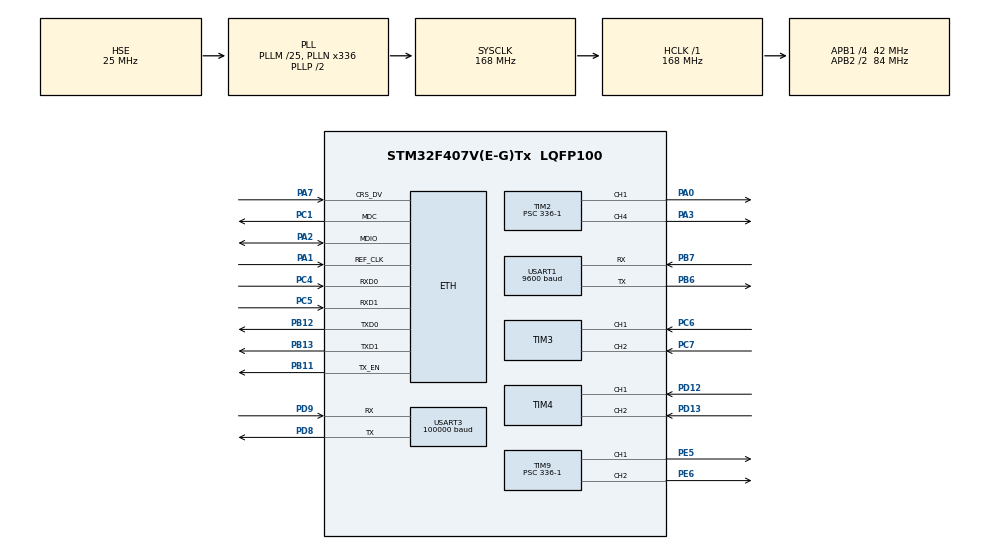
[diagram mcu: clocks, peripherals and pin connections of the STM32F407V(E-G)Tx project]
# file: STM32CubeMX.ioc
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Dma.Request0=USART1_TX
Dma.Request1=USART3_RX
Dma.USART1_TX.0.Direction=DMA_MEMORY_TO_PERIPH
Dma.USART1_TX.0.FIFOMode=DMA_FIFOMODE_DISABLE
Dma.USART1_TX.0.Instance=DMA2_Stream7
Dma.USART1_TX.0.MemDataAlignment=DMA_MDATAALIGN_BYTE
Dma.USART1_TX.0.MemInc=DMA_MINC_ENABLE
Dma.USART1_TX.0.Mode=DMA_NORMAL
Dma.USART1_TX.0.PeriphDataAlignment=DMA_PDATAALIGN_BYTE
Dma.USART1_TX.0.PeriphInc=DMA_PINC_DISABLE
Dma.USART1_TX.0.Priority=DMA_PRIORITY_LOW
Dma.USART3_RX.1.Direction=DMA_PERIPH_TO_MEMORY
Dma.USART3_RX.1.FIFOMode=DMA_FIFOMODE_DISABLE
Dma.USART3_RX.1.Instance=DMA1_Stream1
Dma.USART3_RX.1.MemDataAlignment=DMA_MDATAALIGN_BYTE
Dma.USART3_RX.1.MemInc=DMA_MINC_ENABLE
Dma.USART3_RX.1.Mode=DMA_CIRCULAR
Dma.USART3_RX.1.PeriphDataAlignment=DMA_PDATAALIGN_BYTE
Dma.USART3_RX.1.PeriphInc=DMA_PINC_DISABLE
Dma.USART3_RX.1.Priority=DMA_PRIORITY_LOW
ETH.MediaInterface=HAL_ETH_RMII_MODE
ETH.RxMode=ETH_RXINTERRUPT_MODE
Mcu.Family=STM32F4
Mcu.Name=STM32F407V(E-G)Tx
Mcu.Package=LQFP100
NVIC.DMA1_Stream1_IRQn=true\:4\:0\:true\:false\:true\:false\:true\:true
NVIC.DMA2_Stream7_IRQn=true\:0\:0\:false\:false\:true\:false\:true\:true
NVIC.ETH_IRQn=true\:0\:0\:true\:false\:true\:true\:true\:true
NVIC.ETH_WKUP_IRQn=true\:0\:0\:false\:false\:true\:true\:true\:true
NVIC.PriorityGroup=NVIC_PRIORITYGROUP_4
NVIC.TIM3_IRQn=true\:4\:0\:true\:false\:true\:true\:true\:true
NVIC.TIM4_IRQn=true\:4\:0\:true\:false\:true\:true\:true\:true
NVIC.TIM5_IRQn=true\:4\:0\:true\:false\:true\:true\:true\:true
NVIC.TIM8_TRG_COM_TIM14_IRQn=true\:15\:0\:false\:false\:true\:false\:true\:true
NVIC.TimeBase=TIM8_TRG_COM_TIM14_IRQn
NVIC.TimeBaseIP=TIM14
NVIC.USART1_IRQn=true\:4\:0\:true\:false\:true\:true\:true\:true
NVIC.USART3_IRQn=true\:4\:0\:true\:false\:true\:true\:true\:true
PA0-WKUP.Signal=S_TIM2_CH1_ETR
PA1.Mode=RMII
PA1.Signal=ETH_REF_CLK
PA13.Mode=Serial_Wire
PA13.Signal=SYS_JTMS-SWDIO
PA14.Mode=Serial_Wire
PA14.Signal=SYS_JTCK-SWCLK
PA2.Mode=RMII
PA2.Signal=ETH_MDIO
PA3.Signal=S_TIM2_CH4
PA7.Mode=RMII
PA7.Signal=ETH_CRS_DV
PB11.Mode=RMII
PB11.Signal=ETH_TX_EN
PB12.Mode=RMII
PB12.Signal=ETH_TXD0
PB13.Mode=RMII
PB13.Signal=ETH_TXD1
PB6.Mode=Asynchronous
PB6.Signal=USART1_TX
PB7.Mode=Asynchronous
PB7.Signal=USART1_RX
PC1.Mode=RMII
PC1.Signal=ETH_MDC
PC14-OSC32_IN.Mode=LSE-External-Oscillator
PC14-OSC32_IN.Signal=RCC_OSC32_IN
PC15-OSC32_OUT.Mode=LSE-External-Oscillator
PC15-OSC32_OUT.Signal=RCC_OSC32_OUT
PC4.Mode=RMII
PC4.Signal=ETH_RXD0
PC5.Mode=RMII
PC5.Signal=ETH_RXD1
PC6.Signal=S_TIM3_CH1
PC7.Signal=S_TIM3_CH2
PD12.Signal=S_TIM4_CH1
PD13.Signal=S_TIM4_CH2
PD8.Mode=Asynchronous
PD8.Signal=USART3_TX
PD9.Mode=Asynchronous
PD9.Signal=USART3_RX
PE5.Signal=S_TIM9_CH1
PE6.Signal=S_TIM9_CH2
PH0-OSC_IN.Mode=HSE-External-Oscillator
PH0-OSC_IN.Signal=RCC_OSC_IN
PH1-OSC_OUT.Mode=HSE-External-Oscillator
PH1-OSC_OUT.Signal=RCC_OSC_OUT
ProjectManager.HeapSize=0x200
ProjectManager.StackSize=0x400
ProjectManager.TargetToolchain=MDK-ARM V5.32
RCC.48MHZClocksFreq_Value=84000000
RCC.AHBFreq_Value=168000000
RCC.APB1CLKDivider=RCC_HCLK_DIV4
RCC.APB1Freq_Value=42000000
RCC.APB1TimFreq_Value=84000000
RCC.APB2CLKDivider=RCC_HCLK_DIV2
RCC.APB2Freq_Value=84000000
RCC.APB2TimFreq_Value=168000000
RCC.CortexFreq_Value=168000000
RCC.HCLKFreq_Value=168000000
RCC.HSE_VALUE=25000000
RCC.HSI_VALUE=16000000
RCC.PLLM=25
RCC.PLLN=336
RCC.PLLSourceVirtual=RCC_PLLSOURCE_HSE
RCC.SYSCLKFreq_VALUE=168000000
RCC.SYSCLKSource=RCC_SYSCLKSOURCE_PLLCLK
RCC.VCOOutputFreq_Value=336000000
SH.S_TIM2_CH1_ETR.0=TIM2_CH1,PWM Generation1 CH1
SH.S_TIM2_CH4.0=TIM2_CH4,PWM Generation4 CH4
SH.S_TIM3_CH1.0=TIM3_CH1,Encoder_Interface
SH.S_TIM3_CH2.0=TIM3_CH2,Encoder_Interface
SH.S_TIM4_CH1.0=TIM4_CH1,Encoder_Interface
SH.S_TIM4_CH2.0=TIM4_CH2,Encoder_Interface
SH.S_TIM9_CH1.0=TIM9_CH1,PWM Generation1 CH1
SH.S_TIM9_CH2.0=TIM9_CH2,PWM Generation2 CH2
TIM2.AutoReloadPreload=TIM_AUTORELOAD_PRELOAD_ENABLE
TIM2.Channel-PWM\ Generation1\ CH1=TIM_CHANNEL_1
TIM2.Channel-PWM\ Generation4\ CH4=TIM_CHANNEL_4
TIM2.Period=100-1
TIM2.Prescaler=336-1
TIM3.EncoderMode=TIM_ENCODERMODE_TI12
TIM4.EncoderMode=TIM_ENCODERMODE_TI12
TIM4.IC1Filter=0
TIM4.IC2Filter=15
TIM5.Period=1000-1
TIM5.Prescaler=840-1
TIM9.AutoReloadPreload=TIM_AUTORELOAD_PRELOAD_ENABLE
TIM9.Channel-PWM\ Generation1\ CH1=TIM_CHANNEL_1
TIM9.Channel-PWM\ Generation2\ CH2=TIM_CHANNEL_2
TIM9.Period=100-1
TIM9.Prescaler=336-1
USART1.BaudRate=9600
USART1.Parity=PARITY_EVEN
USART1.VirtualMode=VM_ASYNC
USART1.WordLength=WORDLENGTH_9B
USART3.BaudRate=100000
USART3.Mode=MODE_TX_RX
USART3.Parity=PARITY_EVEN
USART3.StopBits=STOPBITS_2
USART3.VirtualMode=VM_ASYNC
USART3.WordLength=WORDLENGTH_9B
VP_SYS_VS_tim14.Mode=TIM14
VP_TIM2_VS_ClockSourceINT.Mode=Internal
VP_TIM5_VS_ClockSourceINT.Mode=Internal
VP_TIM9_VS_ClockSourceINT.Mode=Internal
board=custom

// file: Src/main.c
/* USER CODE BEGIN Header */
/**
  ******************************************************************************
  * @file           : main.c
  * @brief          : Main program body
  ******************************************************************************
  * @attention
  *
  * Copyright (c) 2025 STMicroelectronics.
  * All rights reserved.
  *
  * This software is licensed under terms that can be found in the LICENSE file
  * in the root directory of this software component.
  * If no LICENSE file comes with this software, it is provided AS-IS.
  *
  ******************************************************************************
  */
/* USER CODE END Header */
#include "main.h"
#include "string.h"

/* USER CODE BEGIN Includes */
#include "RTE_Components.h"
#include CMSIS_device_header
#include "cmsis_os2.h"
#include "rl_net.h"

#include <stdbool.h>
#include "system.h"

/* USER CODE END Includes */

ETH_TxPacketConfig TxConfig;
ETH_DMADescTypeDef  DMARxDscrTab[ETH_RX_DESC_CNT]; /* Ethernet Rx DMA Descriptors */
ETH_DMADescTypeDef  DMATxDscrTab[ETH_TX_DESC_CNT]; /* Ethernet Tx DMA Descriptors */

ETH_HandleTypeDef heth;

TIM_HandleTypeDef htim2;
TIM_HandleTypeDef htim3;
TIM_HandleTypeDef htim4;
TIM_HandleTypeDef htim5;
TIM_HandleTypeDef htim9;

UART_HandleTypeDef huart1;
UART_HandleTypeDef huart3;
DMA_HandleTypeDef hdma_usart1_tx;
DMA_HandleTypeDef hdma_usart3_rx;

void SystemClock_Config(void);
static void MX_GPIO_Init(void);
static void MX_DMA_Init(void);
static void MX_TIM2_Init(void);
static void MX_TIM4_Init(void);
static void MX_TIM9_Init(void);
static void MX_USART3_UART_Init(void);
static void MX_TIM5_Init(void);
static void MX_TIM3_Init(void);
static void MX_USART1_UART_Init(void);
static void MX_ETH_Init(void);

int main(void)
{

  /* MCU Configuration--------------------------------------------------------*/

  /* Reset of all peripherals, Initializes the Flash interface and the Systick. */
  HAL_Init();

  /* Configure the system clock */
  SystemClock_Config();

  /* Initialize all configured peripherals */
  MX_GPIO_Init();
  MX_DMA_Init();
  MX_TIM2_Init();
  MX_TIM4_Init();
  MX_TIM9_Init();
  MX_USART3_UART_Init();
  MX_TIM5_Init();
  MX_TIM3_Init();
  MX_USART1_UART_Init();
  MX_ETH_Init();
  /* USER CODE BEGIN 2 */
  system();
  /* USER CODE END 2 */

  /* Infinite loop */
  while (1)
  {

    /* USER CODE BEGIN 3 */
    //progress will not get here
  }
  /* USER CODE END 3 */
}

void SystemClock_Config(void)
{
  RCC_OscInitTypeDef RCC_OscInitStruct = {0};
  RCC_ClkInitTypeDef RCC_ClkInitStruct = {0};

  /** Configure the main internal regulator output voltage
  */
  __HAL_RCC_PWR_CLK_ENABLE();
  __HAL_PWR_VOLTAGESCALING_CONFIG(PWR_REGULATOR_VOLTAGE_SCALE1);

  /** Initializes the RCC Oscillators according to the specified parameters
  * in the RCC_OscInitTypeDef structure.
  */
  RCC_OscInitStruct.OscillatorType = RCC_OSCILLATORTYPE_HSE;
  RCC_OscInitStruct.HSEState = RCC_HSE_ON;
  RCC_OscInitStruct.PLL.PLLState = RCC_PLL_ON;
  RCC_OscInitStruct.PLL.PLLSource = RCC_PLLSOURCE_HSE;
  RCC_OscInitStruct.PLL.PLLM = 25;
  RCC_OscInitStruct.PLL.PLLN = 336;
  RCC_OscInitStruct.PLL.PLLP = RCC_PLLP_DIV2;
  RCC_OscInitStruct.PLL.PLLQ = 4;
  if (HAL_RCC_OscConfig(&RCC_OscInitStruct) != HAL_OK)
  {
    Error_Handler();
  }

  /** Initializes the CPU, AHB and APB buses clocks
  */
  RCC_ClkInitStruct.ClockType = RCC_CLOCKTYPE_HCLK|RCC_CLOCKTYPE_SYSCLK
                              |RCC_CLOCKTYPE_PCLK1|RCC_CLOCKTYPE_PCLK2;
  RCC_ClkInitStruct.SYSCLKSource = RCC_SYSCLKSOURCE_PLLCLK;
  RCC_ClkInitStruct.AHBCLKDivider = RCC_SYSCLK_DIV1;
  RCC_ClkInitStruct.APB1CLKDivider = RCC_HCLK_DIV4;
  RCC_ClkInitStruct.APB2CLKDivider = RCC_HCLK_DIV2;

  if (HAL_RCC_ClockConfig(&RCC_ClkInitStruct, FLASH_LATENCY_5) != HAL_OK)
  {
    Error_Handler();
  }
}

static void MX_ETH_Init(void)
{

   static uint8_t MACAddr[6];

  heth.Instance = ETH;
  MACAddr[0] = 0x00;
  MACAddr[1] = 0x80;
  MACAddr[2] = 0xE1;
  MACAddr[3] = 0x00;
  MACAddr[4] = 0x00;
  MACAddr[5] = 0x00;
  heth.Init.MACAddr = &MACAddr[0];
  heth.Init.MediaInterface = HAL_ETH_RMII_MODE;
  heth.Init.TxDesc = DMATxDscrTab;
  heth.Init.RxDesc = DMARxDscrTab;
  heth.Init.RxBuffLen = 1524;

  if (HAL_ETH_Init(&heth) != HAL_OK)
  {
    Error_Handler();
  }

  memset(&TxConfig, 0 , sizeof(ETH_TxPacketConfig));
  TxConfig.Attributes = ETH_TX_PACKETS_FEATURES_CSUM | ETH_TX_PACKETS_FEATURES_CRCPAD;
  TxConfig.ChecksumCtrl = ETH_CHECKSUM_IPHDR_PAYLOAD_INSERT_PHDR_CALC;
  TxConfig.CRCPadCtrl = ETH_CRC_PAD_INSERT;

}

static void MX_TIM2_Init(void)
{

  TIM_ClockConfigTypeDef sClockSourceConfig = {0};
  TIM_MasterConfigTypeDef sMasterConfig = {0};
  TIM_OC_InitTypeDef sConfigOC = {0};

  htim2.Instance = TIM2;
  htim2.Init.Prescaler = 336-1;
  htim2.Init.CounterMode = TIM_COUNTERMODE_UP;
  htim2.Init.Period = 100-1;
  htim2.Init.ClockDivision = TIM_CLOCKDIVISION_DIV1;
  htim2.Init.AutoReloadPreload = TIM_AUTORELOAD_PRELOAD_ENABLE;
  if (HAL_TIM_Base_Init(&htim2) != HAL_OK)
  {
    Error_Handler();
  }
  sClockSourceConfig.ClockSource = TIM_CLOCKSOURCE_INTERNAL;
  if (HAL_TIM_ConfigClockSource(&htim2, &sClockSourceConfig) != HAL_OK)
  {
    Error_Handler();
  }
  if (HAL_TIM_PWM_Init(&htim2) != HAL_OK)
  {
    Error_Handler();
  }
  sMasterConfig.MasterOutputTrigger = TIM_TRGO_RESET;
  sMasterConfig.MasterSlaveMode = TIM_MASTERSLAVEMODE_DISABLE;
  if (HAL_TIMEx_MasterConfigSynchronization(&htim2, &sMasterConfig) != HAL_OK)
  {
    Error_Handler();
  }
  sConfigOC.OCMode = TIM_OCMODE_PWM1;
  sConfigOC.Pulse = 0;
  sConfigOC.OCPolarity = TIM_OCPOLARITY_HIGH;
  sConfigOC.OCFastMode = TIM_OCFAST_DISABLE;
  if (HAL_TIM_PWM_ConfigChannel(&htim2, &sConfigOC, TIM_CHANNEL_1) != HAL_OK)
  {
    Error_Handler();
  }
  if (HAL_TIM_PWM_ConfigChannel(&htim2, &sConfigOC, TIM_CHANNEL_4) != HAL_OK)
  {
    Error_Handler();
  }
  HAL_TIM_MspPostInit(&htim2);

}

static void MX_TIM3_Init(void)
{

  TIM_Encoder_InitTypeDef sConfig = {0};
  TIM_MasterConfigTypeDef sMasterConfig = {0};

  htim3.Instance = TIM3;
  htim3.Init.Prescaler = 0;
  htim3.Init.CounterMode = TIM_COUNTERMODE_UP;
  htim3.Init.Period = 65535;
  htim3.Init.ClockDivision = TIM_CLOCKDIVISION_DIV1;
  htim3.Init.AutoReloadPreload = TIM_AUTORELOAD_PRELOAD_DISABLE;
  sConfig.EncoderMode = TIM_ENCODERMODE_TI12;
  sConfig.IC1Polarity = TIM_ICPOLARITY_RISING;
  sConfig.IC1Selection = TIM_ICSELECTION_DIRECTTI;
  sConfig.IC1Prescaler = TIM_ICPSC_DIV1;
  sConfig.IC1Filter = 0;
  sConfig.IC2Polarity = TIM_ICPOLARITY_RISING;
  sConfig.IC2Selection = TIM_ICSELECTION_DIRECTTI;
  sConfig.IC2Prescaler = TIM_ICPSC_DIV1;
  sConfig.IC2Filter = 0;
  if (HAL_TIM_Encoder_Init(&htim3, &sConfig) != HAL_OK)
  {
    Error_Handler();
  }
  sMasterConfig.MasterOutputTrigger = TIM_TRGO_RESET;
  sMasterConfig.MasterSlaveMode = TIM_MASTERSLAVEMODE_DISABLE;
  if (HAL_TIMEx_MasterConfigSynchronization(&htim3, &sMasterConfig) != HAL_OK)
  {
    Error_Handler();
  }

}

static void MX_TIM4_Init(void)
{

  TIM_Encoder_InitTypeDef sConfig = {0};
  TIM_MasterConfigTypeDef sMasterConfig = {0};

  htim4.Instance = TIM4;
  htim4.Init.Prescaler = 0;
  htim4.Init.CounterMode = TIM_COUNTERMODE_UP;
  htim4.Init.Period = 65535;
  htim4.Init.ClockDivision = TIM_CLOCKDIVISION_DIV1;
  htim4.Init.AutoReloadPreload = TIM_AUTORELOAD_PRELOAD_DISABLE;
  sConfig.EncoderMode = TIM_ENCODERMODE_TI12;
  sConfig.IC1Polarity = TIM_ICPOLARITY_RISING;
  sConfig.IC1Selection = TIM_ICSELECTION_DIRECTTI;
  sConfig.IC1Prescaler = TIM_ICPSC_DIV1;
  sConfig.IC1Filter = 0;
  sConfig.IC2Polarity = TIM_ICPOLARITY_RISING;
  sConfig.IC2Selection = TIM_ICSELECTION_DIRECTTI;
  sConfig.IC2Prescaler = TIM_ICPSC_DIV1;
  sConfig.IC2Filter = 15;
  if (HAL_TIM_Encoder_Init(&htim4, &sConfig) != HAL_OK)
  {
    Error_Handler();
  }
  sMasterConfig.MasterOutputTrigger = TIM_TRGO_RESET;
  sMasterConfig.MasterSlaveMode = TIM_MASTERSLAVEMODE_DISABLE;
  if (HAL_TIMEx_MasterConfigSynchronization(&htim4, &sMasterConfig) != HAL_OK)
  {
    Error_Handler();
  }

}

static void MX_TIM5_Init(void)
{

  TIM_ClockConfigTypeDef sClockSourceConfig = {0};
  TIM_MasterConfigTypeDef sMasterConfig = {0};

  htim5.Instance = TIM5;
  htim5.Init.Prescaler = 840-1;
  htim5.Init.CounterMode = TIM_COUNTERMODE_UP;
  htim5.Init.Period = 1000-1;
  htim5.Init.ClockDivision = TIM_CLOCKDIVISION_DIV1;
  htim5.Init.AutoReloadPreload = TIM_AUTORELOAD_PRELOAD_DISABLE;
  if (HAL_TIM_Base_Init(&htim5) != HAL_OK)
  {
    Error_Handler();
  }
  sClockSourceConfig.ClockSource = TIM_CLOCKSOURCE_INTERNAL;
  if (HAL_TIM_ConfigClockSource(&htim5, &sClockSourceConfig) != HAL_OK)
  {
    Error_Handler();
  }
  sMasterConfig.MasterOutputTrigger = TIM_TRGO_RESET;
  sMasterConfig.MasterSlaveMode = TIM_MASTERSLAVEMODE_DISABLE;
  if (HAL_TIMEx_MasterConfigSynchronization(&htim5, &sMasterConfig) != HAL_OK)
  {
    Error_Handler();
  }

}

static void MX_TIM9_Init(void)
{

  TIM_ClockConfigTypeDef sClockSourceConfig = {0};
  TIM_OC_InitTypeDef sConfigOC = {0};

  htim9.Instance = TIM9;
  htim9.Init.Prescaler = 336-1;
  htim9.Init.CounterMode = TIM_COUNTERMODE_UP;
  htim9.Init.Period = 100-1;
  htim9.Init.ClockDivision = TIM_CLOCKDIVISION_DIV1;
  htim9.Init.AutoReloadPreload = TIM_AUTORELOAD_PRELOAD_ENABLE;
  if (HAL_TIM_Base_Init(&htim9) != HAL_OK)
  {
    Error_Handler();
  }
  sClockSourceConfig.ClockSource = TIM_CLOCKSOURCE_INTERNAL;
  if (HAL_TIM_ConfigClockSource(&htim9, &sClockSourceConfig) != HAL_OK)
  {
    Error_Handler();
  }
  if (HAL_TIM_PWM_Init(&htim9) != HAL_OK)
  {
    Error_Handler();
  }
  sConfigOC.OCMode = TIM_OCMODE_PWM1;
  sConfigOC.Pulse = 0;
  sConfigOC.OCPolarity = TIM_OCPOLARITY_HIGH;
  sConfigOC.OCFastMode = TIM_OCFAST_DISABLE;
  if (HAL_TIM_PWM_ConfigChannel(&htim9, &sConfigOC, TIM_CHANNEL_1) != HAL_OK)
  {
    Error_Handler();
  }
  if (HAL_TIM_PWM_ConfigChannel(&htim9, &sConfigOC, TIM_CHANNEL_2) != HAL_OK)
  {
    Error_Handler();
  }
  HAL_TIM_MspPostInit(&htim9);

}

static void MX_USART1_UART_Init(void)
{

  huart1.Instance = USART1;
  huart1.Init.BaudRate = 9600;
  huart1.Init.WordLength = UART_WORDLENGTH_9B;
  huart1.Init.StopBits = UART_STOPBITS_1;
  huart1.Init.Parity = UART_PARITY_EVEN;
  huart1.Init.Mode = UART_MODE_TX_RX;
  huart1.Init.HwFlowCtl = UART_HWCONTROL_NONE;
  huart1.Init.OverSampling = UART_OVERSAMPLING_16;
  if (HAL_UART_Init(&huart1) != HAL_OK)
  {
    Error_Handler();
  }

}

static void MX_USART3_UART_Init(void)
{

  huart3.Instance = USART3;
  huart3.Init.BaudRate = 100000;
  huart3.Init.WordLength = UART_WORDLENGTH_9B;
  huart3.Init.StopBits = UART_STOPBITS_2;
  huart3.Init.Parity = UART_PARITY_EVEN;
  huart3.Init.Mode = UART_MODE_TX_RX;
  huart3.Init.HwFlowCtl = UART_HWCONTROL_NONE;
  huart3.Init.OverSampling = UART_OVERSAMPLING_16;
  if (HAL_UART_Init(&huart3) != HAL_OK)
  {
    Error_Handler();
  }

}

static void MX_DMA_Init(void)
{

  /* DMA controller clock enable */
  __HAL_RCC_DMA2_CLK_ENABLE();
  __HAL_RCC_DMA1_CLK_ENABLE();

  /* DMA interrupt init */
  /* DMA1_Stream1_IRQn interrupt configuration */
  HAL_NVIC_SetPriority(DMA1_Stream1_IRQn, 4, 0);
  HAL_NVIC_EnableIRQ(DMA1_Stream1_IRQn);
  /* DMA2_Stream7_IRQn interrupt configuration */
  HAL_NVIC_SetPriority(DMA2_Stream7_IRQn, 0, 0);
  HAL_NVIC_EnableIRQ(DMA2_Stream7_IRQn);

}

static void MX_GPIO_Init(void)
{

  /* GPIO Ports Clock Enable */
  __HAL_RCC_GPIOE_CLK_ENABLE();
  __HAL_RCC_GPIOC_CLK_ENABLE();
  __HAL_RCC_GPIOH_CLK_ENABLE();
  __HAL_RCC_GPIOA_CLK_ENABLE();
  __HAL_RCC_GPIOB_CLK_ENABLE();
  __HAL_RCC_GPIOD_CLK_ENABLE();

}

void HAL_TIM_PeriodElapsedCallback(TIM_HandleTypeDef *htim)
{
  if (htim->Instance == TIM14)
  {
    HAL_IncTick();
  }
}

void Error_Handler(void)
{
  __disable_irq();
  while (1)
  {
  }
}
